# GD32G5x3 register map
File version: 1.0
CPU: CM33 r2p1, little endian, MPU, FPU, 4 interrupt priority bits
Registers are 32-bit, read-write, reset 0x0 unless marked. A register's access mark holds for its fields unless they carry their own. Offsets are from the block's base; [hi:lo] are bit positions; {n}, {i} and the like mark numbered series.

## HRTIMER_MASTER_TIMER — Super High-Resolution Timer
Base 0x40015800
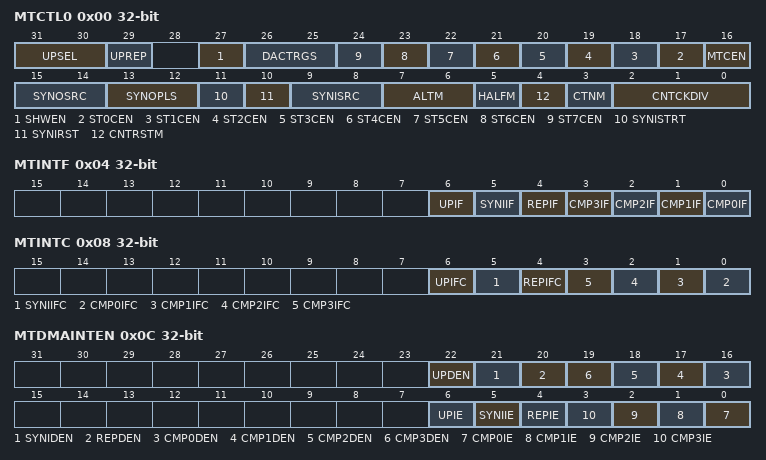
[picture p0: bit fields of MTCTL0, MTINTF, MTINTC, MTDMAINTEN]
0x00 MTCTL0 — HRTIMER Master_TIMER control register 0
  [31:30] UPSEL — Update event selection
  [29] UPREP — Update event generated by repetition event
  [27] SHWEN — Shadow registers enable
  [26:25] DACTRGS — Trigger source to DAC
  [n+17] ST{n}CEN (n=0..7) — The counter of Slave_TIMER{n} enable
  [16] MTCEN — The counter of Master_TIMER enable
  [15:14] SYNOSRC — Synchronization output source
  [13:12] SYNOPLS — Synchronization output pulse
  [11] SYNISTRT — Synchronization input start counter
  [10] SYNIRST — Synchronization input reset counter
  [9:8] SYNISRC — Synchronization input source
  [7:6] ALTM — Alternate mode
  [5] HALFM — Half mode
  [4] CNTRSTM — Counter reset mode
  [3] CTNM — Continuous mode
  [2:0] CNTCKDIV — Counter clock division
0x04 MTINTF ro — HRTIMER Master_TIMER interrupt flag register
  [6] UPIF — Update interrupt flag
  [5] SYNIIF — Synchronization input interrupt flag
  [4] REPIF — Repetition interrupt flag
  [n] CMP{n}IF (n=0..3) — Compare {n} interrupt flag
0x08 MTINTC wo — HRTIMER Master_TIMER interrupt flag clear register
  [6] UPIFC — Clear update interrupt flag
  [5] SYNIIFC — Clear synchronization input interrupt flag
  [4] REPIFC — Clear repetition interrupt flag
  [n] CMP{n}IFC (n=0..3) — Clear compare {n} interrupt flag
0x0C MTDMAINTEN — HRTIMER Master_TIMER DMA and interrupt enable register
  [22] UPDEN — Update DMA request enable
  [21] SYNIDEN — Synchronization input DMA request enable
  [20] REPDEN — Repetition DMA request enable
  [n+16] CMP{n}DEN (n=0..3) — Compare {n} DMA request enable
  [6] UPIE — Update interrupt enable
  [5] SYNIIE — Synchronization input interrupt enable
  [4] REPIE — Repetition interrupt enable
  [n] CMP{n}IE (n=0..3) — Compare {n} interrupt enable
0x10 MTCNT — HRTIMER Master_TIMER counter register
  [15:0] CNT — The current counter value
0x14 MTCAR reset 0xFFDF — HRTIMER Master_TIMER counter auto reload register
  [15:0] CARL — Counter auto reload value
0x18 MTCREP — HRTIMER Master_TIMER counter repetition register
  [7:0] CREP — Counter repetition value
0x1C MTCMP0V — HRTIMER Master_TIMER compare 0 value register
  [15:0] CMP0VAL — Compare 0 value
{0x20+4i} MTCMP{i}V (i=1..3) — HRTIMER Master_TIMER compare {i} value register
  [15:0] CMP{i}VAL — Compare {i} value

## NVIC — Nested Vectored Interrupt Controller
Base 0xE000E100
0x00 ISER — Interrupt Set Enable Register
  [31:0] SETENA
0x80 ICER — Interrupt Clear Enable Register
  [31:0] CLRENA
0x100 ISPR — Interrupt Set-Pending Register
  [31:0] SETPEND
0x180 ICPR — Interrupt Clear-Pending Register
  [31:0] CLRPEND
0x200 IABR — Interrupt Active bit Register
{0x300+i} IPR{i} 8-bit (i=0..67) — Interrupt Priority Register {i}
  [7:0] PRI_{i:02}
0xE00 STIR wo — Software Trigger Interrupt Register

## PMU — Power management unit
Base 0x40007000
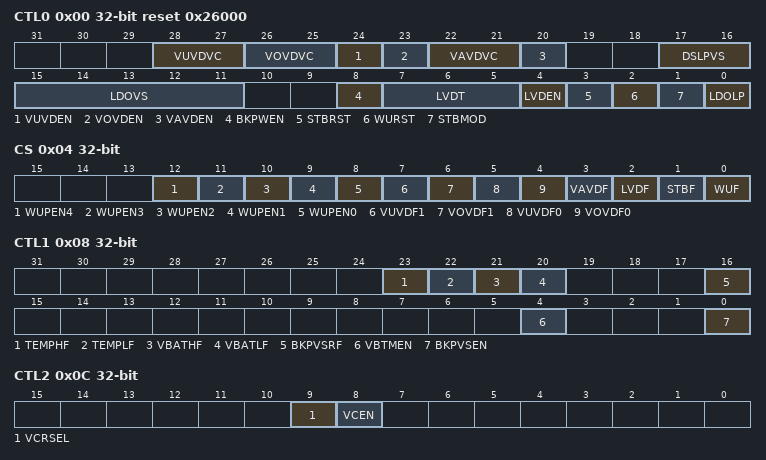
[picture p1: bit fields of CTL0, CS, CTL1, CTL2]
0x00 CTL0 reset 0x26000 — Control register 0
  [28:27] VUVDVC — V1.1v under voltage detector voltage level configure bits
  [26:25] VOVDVC — V1.1v over voltage detector voltage level configure bits
  [24] VUVDEN — V1.1v Under Voltage Detector Enable
  [23] VOVDEN — V1.1v Over Voltage Detector Enable
  [22:21] VAVDVC — VDDA analog voltage detector voltage level configure bits
  [20] VAVDEN — VDDA analog voltage detector voltage enable bit
  [17:16] DSLPVS — Deep-sleep mode voltage scaling selection
  [15:11] LDOVS — LDO output voltage select
  [8] BKPWEN — Backup Domain Write Enable
  [7:5] LVDT — Low Voltage Detector Threshold
  [4] LVDEN — Low Voltage Detector Enable
  [3] STBRST — Standby Flag Reset
  [2] WURST — Wakeup Flag Reset
  [1] STBMOD — Standby Mode
  [0] LDOLP — LDO Low Power Mode
0x04 CS access per field — Control and status register 0
  [12] WUPEN4 rw — WKUP Pin4(PC5) Enable
  [11] WUPEN3 rw — WKUP Pin3 (PA2) Enable
  [10] WUPEN2 rw — WKUP Pin2 (PE6) Enable
  [9] WUPEN1 rw — WKUP Pin1 (PC13) Enable
  [8] WUPEN0 rw — WKUP Pin0 (PA0) Enable (EWUP)
  [7] VUVDF1 ro — V1
  [6] VOVDF1 ro — V1
  [5] VUVDF0 ro — V1
  [4] VOVDF0 ro — V1
  [3] VAVDF ro — VDDA analog voltage detector voltage output on VDDA flag bit
  [2] LVDF ro — Low Voltage Detector Status Flag
  [1] STBF ro — Standby Flag
  [0] WUF ro — Wakeup Flag
0x08 CTL1 access per field — Control register 1
  [23] TEMPHF ro — Temperature level monitoring versus high threshold
  [22] TEMPLF ro — Temperature level monitoring versus low threshold
  [21] VBATHF ro — VBAT level monitoring versus high threshold
  [20] VBATLF ro — VBAT level monitoring versus low threshold
  [16] BKPVSRF ro — Bandgap Voltage Reference ready BRRDY
  [4] VBTMEN rw — VBAT and temperature monitoring enable
  [0] BKPVSEN rw — Bandgap Voltage Reference(BGR) enable
0x0C CTL2 — Control register 2
  [9] VCRSEL — VBAT battery charging resistor selection
  [8] VCEN — VBAT battery charging enable
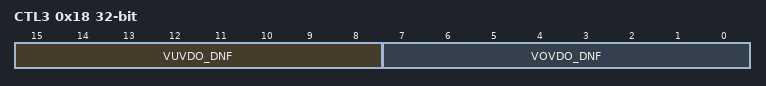
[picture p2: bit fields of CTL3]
0x18 CTL3 — Control register 3
  [15:8] VUVDO_DNF — VUVD analog output digital noise filter
  [7:0] VOVDO_DNF — VOVD analog output digital noise filter
